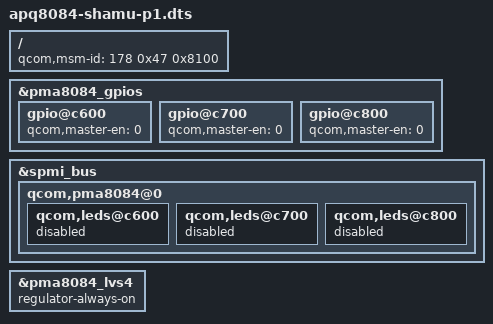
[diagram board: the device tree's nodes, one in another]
/* Copyright (c) 2013, The Linux Foundation. All rights reserved.
 * Copyright (c) 2014 Motorola Mobility LLC
 *
 * This program is free software; you can redistribute it and/or modify
 * it under the terms of the GNU General Public License version 2 and
 * only version 2 as published by the Free Software Foundation.
 *
 * This program is distributed in the hope that it will be useful,
 * but WITHOUT ANY WARRANTY; without even the implied warranty of
 * MERCHANTABILITY or FITNESS FOR A PARTICULAR PURPOSE.  See the
 * GNU General Public License for more details.
 */

/dts-v1/;

#include "qcom/apq8084.dtsi"
#include "apq8084-shamu/apq8084-shamu.dtsi"

/ {
	qcom,msm-id = <178 0x47 0x8100>;
};

&pma8084_gpios {
	gpio@c600 { /* GPIO 7 RED LED */
		qcom,master-en = <0>;		/* Disable GPIO */
	};

	gpio@c700 { /* GPIO 8 GREEN LED */
		qcom,master-en = <0>;		/* Disable GPIO */
	};

	gpio@c800 { /* GPIO 9 BLUE LED */
		qcom,master-en = <0>;		/* Disable GPIO */
	};
};

&spmi_bus {
	qcom,pma8084@0 {
		qcom,leds@c600 {
			status = "disabled";
		};

		qcom,leds@c700 {
			status = "disabled";
		};

		qcom,leds@c800 {
			status = "disabled";
		};
	};
};

&pma8084_lvs4 {
	regulator-always-on;
};
